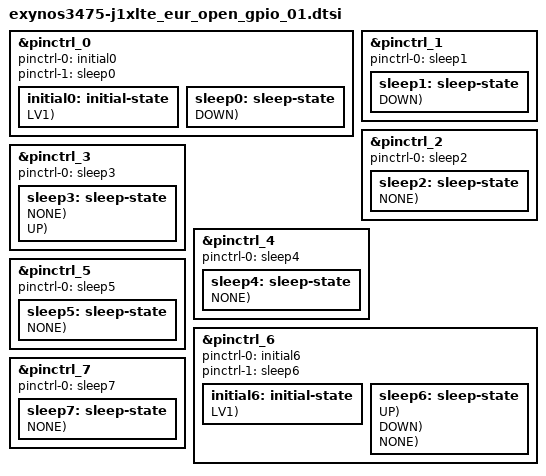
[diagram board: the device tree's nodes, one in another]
/*
 * Copyright (c) 2015 Samsung Electronics Co., Ltd.
 *		http://www.samsung.com
 *
 * This program is free software; you can redistribute it and/or modify
 * it under the terms of the GNU General Public License version 2 as
 * published by the Free Software Foundation.
*/


#include "exynos_gpio_config_macros.dtsi"

// 0x139B_0000 (ALIVE): gpa0~1, gpq0
&pinctrl_0 {
	pinctrl-names = "default", "sleep";
	pinctrl-0 = <&initial0>;
	pinctrl-1 = <&sleep0>;
	initial0: initial-state {
		PIN_OUT_SET(gpa0-5, 0, LV1);	/* MOT_LDO_EN */
		PIN_IN(gpa1-0, NONE, LV1);	/* ACC_INT_N */
		PIN_IN(gpq0-0, DOWN, LV1);	/* NC */
	};
	sleep0: sleep-state {
		PIN_SLP(gpa0-5, INPUT, DOWN);	/* MOT_LDO_EN */
	};
};

// 0x148F_0000 (DISPAUD, Display and Audio): gpz0~1
&pinctrl_1 {
	pinctrl-names = "sleep";
	pinctrl-0 = <&sleep1>;
	sleep1: sleep-state {
		PIN_SLP(gpz0-0, INPUT, DOWN);	/* BT_PCM_SYNC */
		PIN_SLP(gpz0-1, INPUT, DOWN);	/* BT_PCM_CLK */
		PIN_SLP(gpz0-2, INPUT, DOWN);	/* BT_PCM_D_IN */
		PIN_SLP(gpz0-3, INPUT, DOWN);	/* BT_PCM_D_OUT */

		PIN_SLP(gpz1-0, INPUT, DOWN);	/* CODEC_I2S_LRCK */
		PIN_SLP(gpz1-1, INPUT, DOWN);	/* PM_PCM_CLK */
		PIN_SLP(gpz1-2, INPUT, DOWN);	/* CODEC_I2S_SDI */
		PIN_SLP(gpz1-3, INPUT, DOWN);	/* CODEC_I2S_SDO */
	};
};

// 0x138E_0000 (ESE): gpc4
&pinctrl_2 {
	pinctrl-names = "sleep";
	pinctrl-0 = <&sleep2>;
	sleep2: sleep-state {
		PIN_SLP(gpc4-0, INPUT, NONE);	/* SENSOR_SDA_1P8 */
		PIN_SLP(gpc4-1, INPUT, NONE);	/* SENSOR_SCL_1P8 */
		PIN_SLP(gpc4-2, OUT1, NONE);	/* FG_I2C_SDA */
		PIN_SLP(gpc4-3, OUT1, NONE);	/* FG_I2C_SCL */
	};
};

// 0x1375_0000 (FSYS): gpr0~4
&pinctrl_3 {
	pinctrl-names = "sleep";
	pinctrl-0 = <&sleep3>;
	sleep3: sleep-state {
		PIN_SLP(gpr0-1, INPUT, NONE);	/* EMMC_CMD */
		PIN_SLP(gpr2-1, INPUT, UP);	/* WLAN_CMD */
		PIN_SLP(gpr3-0, INPUT, UP);	/* WLAN_D0 */
		PIN_SLP(gpr3-1, INPUT, UP);	/* WLAN_D1 */
		PIN_SLP(gpr3-2, INPUT, UP);	/* WLAN_D2 */
		PIN_SLP(gpr3-3, INPUT, UP);	/* WLAN_D3 */
	};
};

// 0x104E_0000 (MIF): gpm0
&pinctrl_4 {
	pinctrl-names = "sleep";
	pinctrl-0 = <&sleep4>;
	sleep4: sleep-state {
		PIN_SLP(gpm0-0, PREV, NONE);	/* PMIC_I2C_SDA */
		PIN_SLP(gpm0-1, PREV, NONE);	/* PMIC_I2C_SCL */
	};
};

// 0x138C_0000 (NFC): gpc2
&pinctrl_5 {
	pinctrl-names = "sleep";
	pinctrl-0 = <&sleep5>;
	sleep5: sleep-state {
		PIN_SLP(gpc2-0, INPUT, NONE);	/* NFC_I2C_SDA */
		PIN_SLP(gpc2-1, INPUT, NONE);	/* NFC_I2C_SCL */
		PIN_SLP(gpc2-2, PREV, NONE);	/* NFC_PD */
		PIN_SLP(gpc2-3, PREV, NONE); 	/* NFC_CLK_REQ */
	};
};

// 0x139C_0000 (TOP): gpb0~1, gpc0~1, gpd0~2, gpe0, gpf0~1
&pinctrl_6 {
	pinctrl-names = "default","sleep";
	pinctrl-0 = <&initial6>;
	pinctrl-1 = <&sleep6>;
	initial6: initial-state {
		PIN_IN(gpc0-1, DOWN, LV1);	/* LCD_ESD_DET */

		PIN_OUT_SET(gpd0-0, 1, LV1);	/* IF_PMIC_RST */

		PIN_IN(gpd1-2, DOWN, LV1);	/* FG_ERR */

		PIN_IN(gpd1-7, NONE, LV1);	/* HW_REV2 */

		PIN_IN(gpf1-2, NONE, LV1);	/* HW_REV0 */
		PIN_IN(gpf1-3, NONE, LV1);	/* HW_REV1 */
		PIN_IN(gpd1-6, NONE, LV1);	/* LCD_ID */
	};
	sleep6: sleep-state {
		PIN_SLP(gpb0-0, INPUT, UP);	/* GPS_UART_RXD */
		PIN_SLP(gpb0-1, OUT1, UP);	/* GPS_UART_TXD */
		PIN_SLP(gpb0-2, INPUT, DOWN);	/* GPS_UART_CTS */
		PIN_SLP(gpb0-3, OUT0, DOWN);	/* GPS_UART_RTS */
		PIN_SLP(gpb0-4, INPUT, UP);	/* BT_UART_RXD */
		PIN_SLP(gpb0-5, OUT1, UP);	/* BT_UART_TXD */
		PIN_SLP(gpb0-6, INPUT, UP);	/* BT_UART_CTS_N */
		PIN_SLP(gpb0-7, OUT1, UP);	/* BT_UART_RTS_N */

		PIN_SLP(gpc0-0, OUT0, NONE);	/* XBOOT_LDO */
		PIN_SLP(gpc0-1, INPUT, DOWN);	/* LCD_ESD_DET */
		PIN_SLP(gpc0-2, PREV, NONE);	/* 10K PU(DS/SS) */

		PIN_SLP(gpc1-0, INPUT, NONE);	/* IF_PMIC_I2C_SDA */
		PIN_SLP(gpc1-1, INPUT, NONE);	/* IF_PMIC_I2C_SCL */
		PIN_SLP(gpc1-2, INPUT, NONE);	/* TOUCH_KEY_SDA_1P8 */
		PIN_SLP(gpc1-3, INPUT, NONE);	/* TOUCH_KEY_SCL_1P8 */

		PIN_SLP(gpd0-0, OUT1, NONE);	/* IF_PMIC_RST */
		PIN_SLP(gpd0-1, PREV, NONE);	/* PM_WRSTBI */
		PIN_SLP(gpd0-2, INPUT, DOWN);	/* MAIN_CAM_RST_N */
		PIN_SLP(gpd0-3, OUT0, NONE);	/* GPS_EN */
		PIN_SLP(gpd0-4, INPUT, DOWN);	/* VTCAM_RST_N */
		PIN_SLP(gpd0-5, OUT0, NONE);	/* LCD_LDO_EN */
		PIN_SLP(gpd0-6, INPUT, DOWN);	/* NC */
		PIN_SLP(gpd0-7, PREV, NONE);	/* CAM_TORCH_EN */

		PIN_SLP(gpd1-0, INPUT, DOWN);	/* CAM_CORE_EN */
		PIN_SLP(gpd1-1, OUT1, NONE);	/* TOUCH_KEY_EN */
		PIN_SLP(gpd1-2, INPUT, DOWN);	/* FG_ERR */
		PIN_SLP(gpd1-3, PREV, DOWN);	/* NFC FIRMWARE */
		PIN_SLP(gpd1-4, PREV, NONE);	/* WL_REG_ON */
		PIN_SLP(gpd1-5, INPUT, NONE);	/* TSP_INT */
		PIN_SLP(gpd1-6, INPUT, NONE);	/* LCD_ID */
		PIN_SLP(gpd1-7, INPUT, NONE);	/* HW_REV2 */

		PIN_SLP(gpd2-0, PREV, UP);	/* BT_REG_ON */
		PIN_SLP(gpd2-1, OUT0, DOWN);	/* BT_DEV_WAKE */
		PIN_SLP(gpd2-2, INPUT, DOWN);	/* MIPI_DSI0_RESET_N */
		PIN_SLP(gpd2-3, INPUT, DOWN);	/* CAM_FLASH_EN */

		PIN_SLP(gpe0-0, INPUT, DOWN);	/* MAIN_CAM_MCLK */
		PIN_SLP(gpe0-1, INPUT, DOWN);	/* VT_CAM_MCLK */
		PIN_SLP(gpe0-2, INPUT, DOWN);	/* GPIO_CAM_AVDD_EN */

		PIN_SLP(gpf0-0, INPUT, DOWN);	/* CAM_I2C_SDA */
		PIN_SLP(gpf0-1, INPUT, DOWN);	/* CAM_I2C_SCL */
		PIN_SLP(gpf0-2, INPUT, DOWN);	/* VTCAM_STBY */
		PIN_SLP(gpf0-3, INPUT, DOWN);	/* CAM_STBY */

		PIN_SLP(gpf1-0, INPUT, DOWN);	/* NC */
		PIN_SLP(gpf1-1, INPUT, DOWN);	/* NC */
		PIN_SLP(gpf1-2, INPUT, NONE);	/* HW_REV0 */
		PIN_SLP(gpf1-3, INPUT, NONE);	/* HW_REV1 */
	};
};

// 0x138D_0000 (TOUCH): gpc3
&pinctrl_7 {
	pinctrl-names = "sleep";
	pinctrl-0= <&sleep7>;
	sleep7: sleep-state {
		PIN_SLP(gpc3-0, INPUT, NONE);	/* TSP_I2C_SDA */
		PIN_SLP(gpc3-1, INPUT, NONE);	/* TSP_I2C_SCL */
		PIN_SLP(gpc3-2, OUT0, NONE);	/* TSP_LDO_EN */
	};
};
